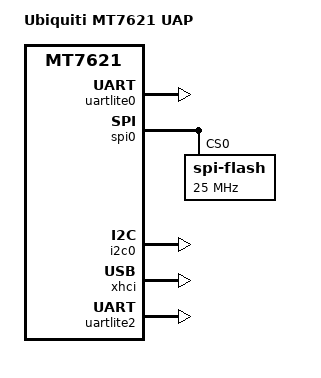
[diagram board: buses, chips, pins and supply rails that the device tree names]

/dts-v1/;
#include "mt7621.dtsi"

/ {
    model = "Ubiquiti MT7621 UAP";
    compatible = "ubiquiti,mt7621-uap";

    aliases {
        spi0 = &spi0;
        serial0 = &uartlite0;
    };

    chosen {
        stdout-path = "serial0:115200n8";
    };

    signature {

        key-uap_mt7621 {
            rsa,r-squared = <0x993ffbd9 0x3242aac5 0x90935874 0x1670a815 0x2341ed87 0x9a1385f2 0xbb2b66f6 0x22d74384 0x9714e516 0xc595a43c 0x6bc94e1 0x259499d8 0xc1ef1ecb 0x763f200 0xffe5389e 0x84d7b32b 0x5d6a513a 0x17f58e87 0x9d8d3d3d 0xec324b02 0xc5ff2e1a 0x9a93b4fa 0x5c8c6d69 0x232c1fd8 0xf0c4d161 0x96653b56 0x2a0476f5 0x1b461a65 0x18f08922 0xf74b400f 0xa7f814f2 0x17cf4a09 0xc7dace47 0x87eef457 0x99c0ad85 0x21580996 0xf48b9f19 0x23a4ab53 0x63abd127 0x564e5df0 0x526caee5 0xd23bb132 0x5840f1ee 0x7579ebe6 0x11121ad8 0xec66519b 0x2dfdfb6e 0xd3f0a4c4 0x15438b7c 0xc43264e7 0x7c07c5fc 0x610350e7 0x7fe69e00 0x9a9ae204 0x30f2ef5 0x68f78dd0 0xa3cc8489 0x65a67fc4 0x760637cb 0x25993ac9 0xfcd064b 0x62a2b9c8 0x8d6c950e 0x6b8d89fa>;
            rsa,modulus = <0xab5b267f 0x4a4e4ad6 0x40646d73 0xbd16f6ce 0x4ea8baad 0xfce9ffcf 0xf1b07c57 0x37e18dc6 0x7873ae8c 0x9f183a82 0x986d33ae 0x30a36107 0xc6ec29e1 0xb5b542f2 0x7bd4f9a7 0x29019998 0x6b0469e8 0xccff7c92 0xbd2ab6bc 0x8082b0ca 0xcf290567 0x4f7294eb 0x8bd284e4 0x408c3cdc 0x8bdcfac 0x5bfc717 0x1077f3fc 0xea561d2e 0x8eaee6ec 0x23e2ce52 0xb138d77f 0x17bd38a2 0x769bb67f 0xf3edd7a1 0xe5ee57a4 0x22a9e4ac 0x1545cc1d 0x56703530 0x494974ca 0xdbf7299b 0x6006cfcd 0x351feb5 0x5a1336d1 0x1558c966 0xe1265b78 0x13e72170 0xd0fb77df 0x7e5d87b1 0xe30e60f5 0x242acae3 0x845acec5 0xedd981f3 0x485e017d 0x7f7a6f18 0xd2e54e42 0x4cf6c522 0xe3af8731 0x6731de3b 0x713ff6dd 0x42087d65 0xecd341c 0xeee65f9b 0xd8c2048a 0x9ab0ff23>;
            rsa,exponent = <0x0 0x10001>;
            rsa,n0-inverse = <0xdda7d775>;
            rsa,num-bits = <0x800>;
            required = "conf";
            algo = "sha1,rsa2048";
            key-name-hint = "uap_mt7621";
        };

        key-uap6_mt7621 {
            required = "conf";
			rsa,r-squared = <0xdc77754b 0xef2c7b07 0x5a28363f 0xdbb52c46 0x7c7e3525 0x2f4859d2 0xc0e4bb3e 0x5ba7ba63 0xeed9f221 0x247861ad 0x933e0610 0x1bda02bf 0x7b0df0cf 0xb40be1ae 0xe5b05426 0x178c3bb5 0x1812d7e7 0x51e5aafd 0x4e4b8bd0 0x124cc5a6 0xf080683c 0x2ecee3fc 0x32ff63fe 0x6a6ec189 0xd4ca53c5 0xc952c167 0xcd3b7c79 0xb0279299 0x7c14912b 0xf8ec0519 0x717b90c2 0x99270b52 0x691d5e40 0xb33d793 0xb3fe1361 0x2fb50824 0x5f5f7313 0x6b96e46f 0x5702b0b6 0x1ea22391 0x5cc38d52 0xef320b7e 0x526cc5d 0xa888c228 0xcdba8108 0x8051303a 0xb906d985 0x72fd982e 0x5b4f3f53 0xbf739bd7 0x8ffd7dde 0xa15681fa 0x19e273cf 0x7714a73b 0xa5c82e77 0x4cd8bf66 0xe1682a32 0x9fe3e70f 0xfe9b0c29 0xe044d788 0x20e6e630 0xbec66e02 0x9b2eb43a 0x53c92ed9>;
			rsa,modulus = <0xee16a98c 0xdf1a9bcc 0xe4c84add 0x24793261 0x6902abfd 0x402e68d0 0x3e4957b 0xa25736e0 0x68eb0faf 0xac94259 0xd5105d86 0x511ec79a 0x89ae945 0xb35de545 0xd83e6b12 0x1c3234df 0xc409c684 0xc36a3264 0x2e3b15c8 0xc914be4 0x36ff2041 0xbbae6979 0x7ba5eb5c 0x3afd9464 0xf662d654 0xb1350366 0xc4af4d7b 0xce754da7 0x68d3d7fa 0x67d587d 0x1bbef5a9 0xc18f9ac 0x78c5703e 0xdbcc39c5 0xa3e73e77 0xd5268460 0x77c44f85 0xcaf92a02 0xa7a75651 0xc38a239f 0xaa6805ef 0x95a60198 0xaf4d3c00 0x53106a48 0x11e03883 0x350c3953 0x9905162c 0x42bd08eb 0x54f0b28a 0xc37ed670 0x9ac65ad0 0xe8f4260c 0xb196c00 0x8cf8bfe6 0xdd192b8 0x4f7bb7b2 0xccfa50f9 0xad9e0228 0x2da88dca 0x4a4ab51b 0x3cd76635 0xcdbdce2f 0xf7e3d816 0xf34c2d9b>;
			rsa,exponent = <0x0 0x10001>;
			rsa,n0-inverse = <0xde358f6d>;
			rsa,num-bits = <0x800>;
            algo = "sha1,rsa2048";
            key-name-hint = "uap6_mt7621";
        };
    };
};

&uartlite0 {
    status = "okay";
};

&spi0 {
    spi-max-frequency = <25000000>;
    status = "okay";

    spi-flash@0 {
    #address-cells = <1>;
    #size-cells = <1>;
        compatible = "spi-flash";
        spi-max-frequency = <25000000>;
        reg = <0>;
    };
};

&i2c0 {
    status = "okay";
};

&xhci {
    status = "okay";
};

&uartlite2 {
    status = "okay";
};
